CM_ "IMPORT _honda_common.dbc";
CM_ "IMPORT _bosch_2018.dbc";

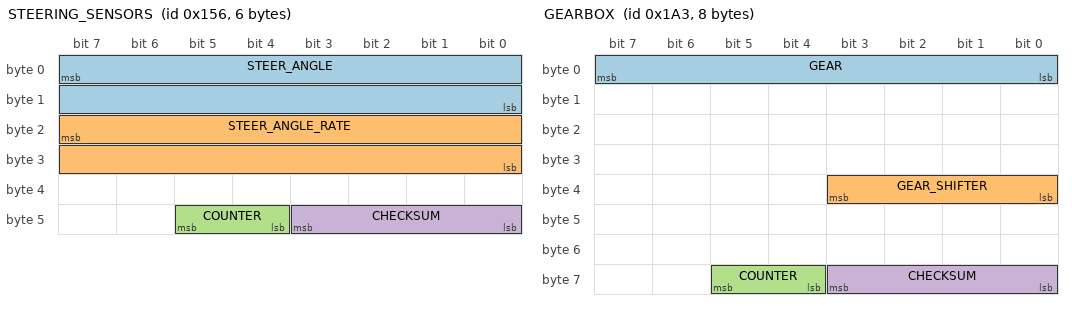
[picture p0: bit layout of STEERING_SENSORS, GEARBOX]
BO_ 342 STEERING_SENSORS: 6 EPS
 SG_ STEER_ANGLE : 7|16@0- (-0.1,0) [-500|500] "deg" EON
 SG_ STEER_ANGLE_RATE : 23|16@0- (-1,0) [-3000|3000] "deg/s" EON
 SG_ COUNTER : 45|2@0+ (1,0) [0|3] "" EON
 SG_ CHECKSUM : 43|4@0+ (1,0) [0|3] "" EON

BO_ 419 GEARBOX: 8 PCM
 SG_ GEAR : 7|8@0+ (1,0) [0|256] "" EON
 SG_ GEAR_SHIFTER : 35|4@0+ (1,0) [0|15] "" EON
 SG_ COUNTER : 61|2@0+ (1,0) [0|3] "" EON
 SG_ CHECKSUM : 59|4@0+ (1,0) [0|3] "" EON

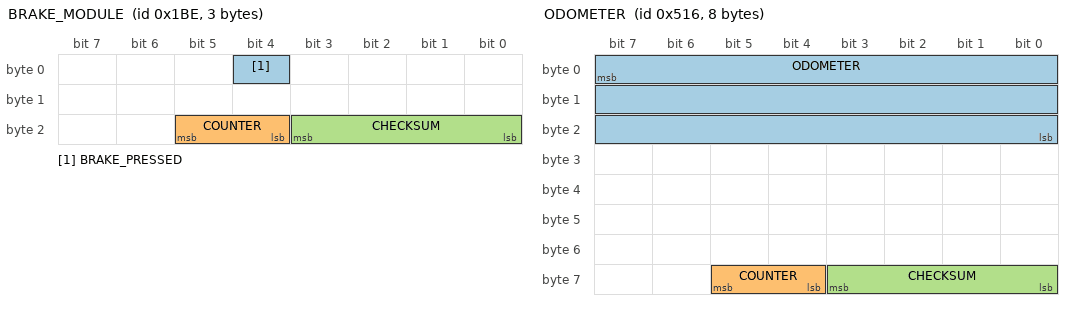
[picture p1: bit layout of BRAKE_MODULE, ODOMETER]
BO_ 446 BRAKE_MODULE: 3 VSA
 SG_ BRAKE_PRESSED : 4|1@0+ (1,0) [0|1] "" XXX
 SG_ COUNTER : 21|2@0+ (1,0) [0|3] "" XXX
 SG_ CHECKSUM : 19|4@0+ (1,0) [0|15] "" XXX

BO_ 927 RADAR_HUD: 8 ADAS
 SG_ ZEROS_BOH : 7|17@0+ (1,0) [0|127] "" BDY
 SG_ APPLY_BRAKES_FOR_CANC : 23|1@0+ (1,0) [0|15] "" BDY
 SG_ ZEROS_BOH2 : 31|8@0+ (1,0) [0|127] "" BDY
 SG_ RESUME_INSTRUCTION : 21|1@0+ (1,0) [0|15] "" BDY
 SG_ ACC_ALERTS : 20|5@0+ (1,0) [0|15] "" BDY
 SG_ LEAD_SPEED : 39|9@0+ (1,0) [0|127] "" BDY
 SG_ LEAD_STATE : 46|3@0+ (1,0) [0|127] "" BDY
 SG_ LEAD_DISTANCE : 43|5@0+ (1,0) [0|31] "" BDY
 SG_ ZEROS_BOH3 : 54|7@0+ (1,0) [0|127] "" BDY
 SG_ COUNTER : 61|2@0+ (1,0) [0|3] "" BDY
 SG_ CHECKSUM : 59|4@0+ (1,0) [0|3] "" BDY

BO_ 1302 ODOMETER: 8 XXX
 SG_ ODOMETER : 7|24@0+ (1,0) [0|16777215] "km" EON
 SG_ COUNTER : 61|2@0+ (1,0) [0|3] "" EON
 SG_ CHECKSUM : 59|4@0+ (1,0) [0|3] "" EON

CM_ SG_ 419 GEAR "10 = reverse, 11 = transition";

VAL_ 419 GEAR_SHIFTER 10 "S" 4 "D" 3 "N" 2 "R" 1 "P" ;
VAL_ 927 ACC_ALERTS 29 "esp_active_acc_canceled" 10 "b_pedal_applied" 9 "speed_too_low" 8 "speed_too_high" 7 "p_brake_applied" 6 "gear_no_d" 5 "seatbelt" 4 "too_steep_downhill" 3 "too_steep_uphill" 2 "too_close" 1 "no_vehicle_ahead" ;
